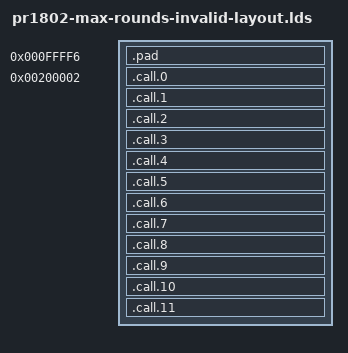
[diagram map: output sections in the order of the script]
SECTIONS {
  . = 0x0ffff6;
  .pad : { *(.pad) }
  . = 0x200002;
  .call.0 : { *(.call.0) }
  .call.1 : { *(.call.1) }
  .call.2 : { *(.call.2) }
  .call.3 : { *(.call.3) }
  .call.4 : { *(.call.4) }
  .call.5 : { *(.call.5) }
  .call.6 : { *(.call.6) }
  .call.7 : { *(.call.7) }
  .call.8 : { *(.call.8) }
  .call.9 : { *(.call.9) }
  .call.10 : { *(.call.10) }
  .call.11 : { *(.call.11) }
}
